# PIC32CM5112SG00048 device description
Architecture: CORTEX-M23; Family: PIC32CM; Series: PIC32CMSG00
Registers are 32-bit, read-write, reset 0x0 unless marked. A register's access mark holds for its fields unless they carry their own. Offsets are from the block's base; [hi:lo] are bit positions; lines under a group give offsets from that group; {n}, {i} and the like mark numbered series; 'fields as' and 'values as' point back to an identical list.

## FUSES_ROMCFG — Defines FUSES module data
Instances: FUSES_ROMCFG 0x0A003000
0x00 DAL reset not defined — DEVICE ACCESS LEVEL Register
  [31:0] DAL_CPU — CPU Device Access Level
0x400 FRCFGBROM reset not defined — PRE-BOOT bromc user Options Register
  [0] BCRCDIS — Boot ROM CRC Disable
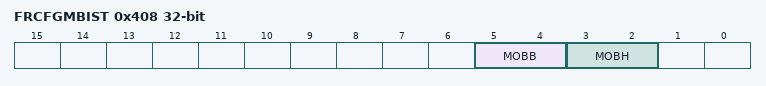
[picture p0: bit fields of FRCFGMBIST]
0x408 FRCFGMBIST reset not defined — PRE-BOOT MBIST user Options Register
  [5:4] MOBB — MBIST On Boot Enable for BACKUP/HIBERNATE Retaining Memory Groups
    1=ENABLED_ANY (MOB runs after any non-BACKUP/HIBERNATE exit reset); 2=ENABLED_POR (MOB runs only after a POR); 3=DISABLED (MOB Disabled)
  [3:2] MOBH — MBIST On Boot Enable for HIBERNATE Only Retaining Memory Groups
    values as MOBB
{0x420+4i} KEYVAL_INTCHK{i} reset 0xFFFFFFFF (i=0..7) — Mapped Fuse Register
{0x440+4i} KEYVAL_CE_ALL{i} reset 0xFFFFFFFF (i=0..7) — Mapped Fuse Register
{0x460+4i} KEYVAL_CE_S_CR{i} reset 0xFFFFFFFF (i=0..7) — Mapped Fuse Register
{0x480+4i} KEYVAL_CE_S{i} reset 0xFFFFFFFF (i=0..7) — Mapped Fuse Register
{0x4A0+4i} KEYVAL_CE_NS_CR{i} reset 0xFFFFFFFF (i=0..7) — Mapped Fuse Register
{0x4C0+4i} KEYVAL_CE_NS{i} reset 0xFFFFFFFF (i=0..7) — Mapped Fuse Register
{0x4E0+4i} KEYVAL_PRG_PG{i} reset 0xFFFFFFFF (i=0..7) — Mapped Fuse Register
{0x500+4i} KEYVAL_SDAL1_{i} reset 0xFFFFFFFF (i=0..7) — Mapped Fuse Register
{0x520+4i} KEYVAL_SDAL0_{i} reset 0xFFFFFFFF (i=0..7) — Mapped Fuse Register
{0x540+4i} KEYVAL_DAL_EL{i} reset 0xFFFFFFFF (i=0..7) — Mapped Fuse Register
{0xC00+4i} PUF_AC[{i}] (i=0..248) reset 0xFFFFFFFF — Mapped Fuse Register

## GCLK — Generic Clock Generator
Instances: GCLK 0x44008000
0x00 CTRLA 8-bit (WSYNC) — Control
  [0] SWRST — Software Reset
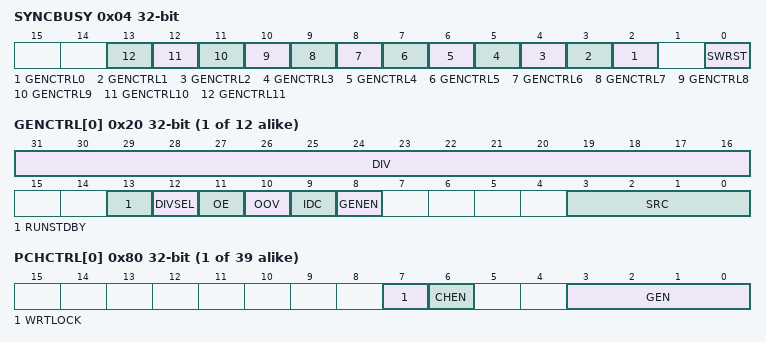
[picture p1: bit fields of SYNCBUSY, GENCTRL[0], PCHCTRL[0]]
0x04 SYNCBUSY ro — Synchronization Busy
  [n+2] GENCTRL{n} (n=0..11) — Generic Clock Generator Control {n} Synchronization Busy bit
  [0] SWRST — Software Reset Synchronization Busy bit
{0x20+4i} GENCTRL[{i}] (i=0..11) (WSYNC) — Generic Clock Generator Control
  [31:16] DIV — Division Factor
  [13] RUNSTDBY — Run in Standby
  [12] DIVSEL — Divide Selection
    0=DIV1 (Divide input directly by divider factor); 1=DIV2 (Divide input by 2^(divider factor+ 1))
  [11] OE — Output Enable
  [10] OOV — Output Off Value
  [9] IDC — Improve Duty Cycle
  [8] GENEN — Generic Clock Generator Enable
  [3:0] SRC — Source Select
    0=XOSC (XOSC oscillator output); 1=GCLK_IN (Generator input pad (GCLK_IO)); 2=GCLK_GEN1 (Generic clock generator 1 output); 3=OSCULP32K (OSCULP32K oscillator output); 4=XOSC32K (XOSC32K oscillator output); 5=DFLL48M (DFLL oscillator output); {v}=PLL0_CLKOUT{v-5} (PLL 0 port CLKOUT{v-5}) (v=6..10)
{0x80+4i} PCHCTRL[{i}] (i=0..38) — Peripheral Clock Control
  [7] WRTLOCK — Write Lock
  [6] CHEN — Channel Enable
  [3:0] GEN — Generic Clock Generator
    {v}=GCLK{v} (Generic clock generator {v}) (v=0..11)

## H2PB — AHB To APB Bridge
Instances: H2PB0 0x44032000, H2PB1 0x44838000, H2PB2 0x4500E000
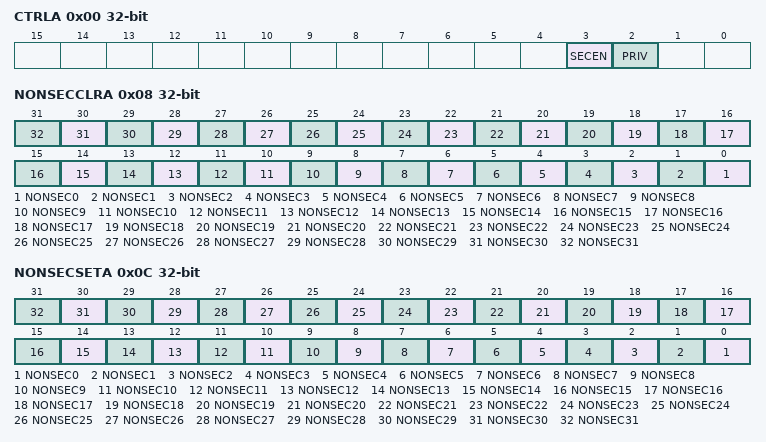
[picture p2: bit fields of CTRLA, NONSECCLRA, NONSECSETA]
0x00 CTRLA — H2PB CONTROL Register
  [3] SECEN — SECEN security enable bit
  [2] PRIV — PRIV privileged access protection bit
0x08 NONSECCLRA (atomic clear) — Non-Security Clear Register A
  [n] NONSEC{n} (n=0..31) — non-security bit for APB Slave k, k=0..31
0x0C NONSECSETA (atomic set) — Non-Security SET Register A
  [n] NONSEC{n} (n=0..31) — non-security bit for APB Slave k, k=0..31

## HMATRIX2 — HSB Matrix
Instances: HMATRIX2 0x44010000
{0x0+4i} MCFG[{i}] (i=0..5) reset 0x2 — Master Configuration
  [2:0] ULBT — Undefined Length Burst Type
    0=INFINITE (Infinite Length); 1=SINGLE (Single Access); 2=FOUR_BEAT (Four Beat Burst); 3=EIGHT_BEAT (Eight Beat Burst); 4=SIXTEEN_BEAT (Sixteen Beat Burst)
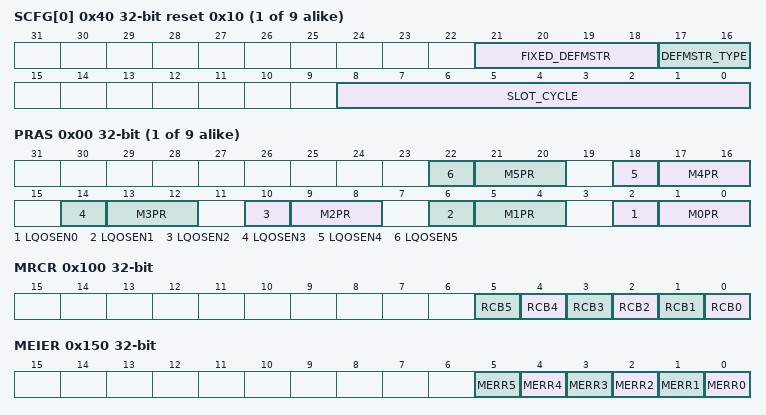
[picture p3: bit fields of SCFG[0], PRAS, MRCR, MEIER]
{0x40+4i} SCFG[{i}] (i=0..8) reset 0x10 — Slave Configuration
  [21:18] FIXED_DEFMSTR — Fixed Index of Default Master
  [17:16] DEFMSTR_TYPE — Default Master Type
    0=NO_DEFAULT (No Default Master. At the end of current slave access, if no other master request is pending, the slave is deconnected from all masters. This resusts in having a one cycle latency for the first transfer of a burst.); 1=LAST_DEFAULT (Last Default Master At the end of current slave access, if no other master request is pending, the slave stay connected with the last master havingaccessed it.This resusts in not having the one cycle latency when the last master re-trying access on the slave.); 2=FIXED_DEFAULT (Fixed Default Master At the end of current slave access, if no other master request is pending, the slave connects with fixed master which numberis in FIXED_DEFMSTR register.This resusts in not having the one cycle latency when the fixed master re-trying access on the slave.)
  [8:0] SLOT_CYCLE — Maximum Number of Allowed Cycles for a Burst
{0x80+8i} PRS[{i}] (i=0..8) group
  0x00 PRAS — Priority A for Slave
    [4n+2] LQOSEN{n} (n=0..5) — Latency Quality Of Service Enable for Master {n}
    [4n+1:4n] M{n}PR (n=0..5) — Master {n} Priority
0x100 MRCR — Master Remap Control
  [all] fields
    0=DIS (Disable remapped address decoding for master); 1=ENA (Enable remapped address decoding for master)
  [n] RCB{n} (n=0..5) — Remap Command Bit for Master {n}
{0x110+4i} SFR[{i}] (i=0..8) — Special Function
  [31:0] SFR — Special Function Register
0x150 MEIER wo reset not defined (atomic set of MEIMR) — Master Error Interrupt Enable
  [n] MERR{n} (n=0..5) — Master {n} Access Error
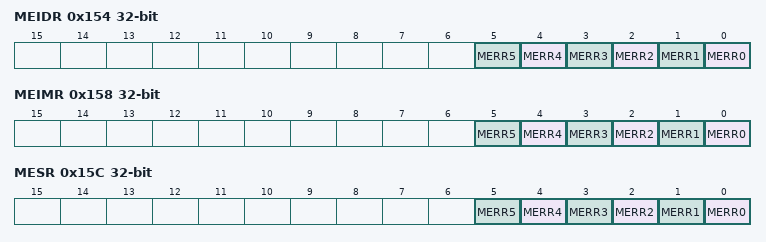
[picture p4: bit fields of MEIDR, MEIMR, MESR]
0x154 MEIDR wo reset not defined (atomic clear of MEIMR) — Master Error Interrupt Disable
  [n] MERR{n} (n=0..5) — Master {n} Access Error
0x158 MEIMR ro reset not defined — Master Error Interrupt Mask
  [n] MERR{n} (n=0..5) — Master {n} Access Error
0x15C MESR ro reset not defined (atomic clear) — Master Error Status
  [n] MERR{n} (n=0..5) — Master {n} Access Error
{0x160+4i} MEAR[{i}] (i=0..5) ro reset not defined — Master Error Address
